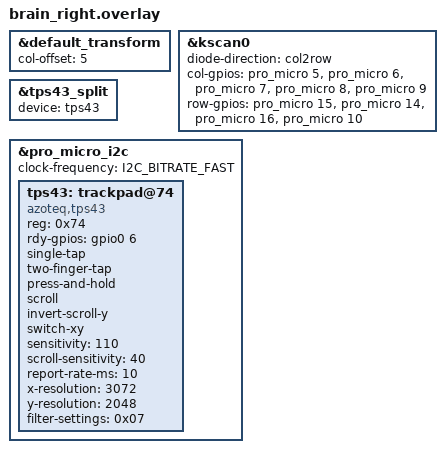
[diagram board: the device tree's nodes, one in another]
/*
 * Copyright (c) 2022 Duccio Breschi
 * Copyright (c) 2023 iamDrakkir
 * SPDX-License-Identifier: MIT
 */

#include "brain.dtsi"
#include <dt-bindings/i2c/i2c.h>

&default_transform {
    col-offset = <5>;
};

&kscan0 {
    diode-direction = "col2row";
    col-gpios
        = <&pro_micro 5 (GPIO_ACTIVE_HIGH)> // COL0
        , <&pro_micro 6 (GPIO_ACTIVE_HIGH)> // COL1
        , <&pro_micro 7 (GPIO_ACTIVE_HIGH)> // COL2
        , <&pro_micro 8 (GPIO_ACTIVE_HIGH)> // COL3
        , <&pro_micro 9 (GPIO_ACTIVE_HIGH)> // COL4
    ;
    row-gpios
        = <&pro_micro 15 (GPIO_ACTIVE_HIGH | GPIO_PULL_DOWN)> // ROW0
        , <&pro_micro 14 (GPIO_ACTIVE_HIGH | GPIO_PULL_DOWN)> // ROW1
        , <&pro_micro 16 (GPIO_ACTIVE_HIGH | GPIO_PULL_DOWN)> // ROW2
        , <&pro_micro 10 (GPIO_ACTIVE_HIGH | GPIO_PULL_DOWN)> // ROW3
    ;
};

/* ─── TPS43 Touchpad via nice!view header pins ─────────────────────────
 *
 * nice!view header (Brain PCB)       TPS43 adapter
 * ────────────────────────────       ─────────────
 * MOSI  (P0.17)  ──────────────►    SDA
 * SCK   (P0.20)  ──────────────►    SCL
 * VCC   (3.3V)   ──────────────►    VCC
 * GND            ──────────────►    GND
 * CS    (P0.06)  ──────────────►    RDY
 */

&tps43_split {
    device = <&tps43>;
};

&pro_micro_i2c {
    status = "okay";
    clock-frequency = <I2C_BITRATE_FAST>;

    tps43: trackpad@74 {
        compatible = "azoteq,tps43";
        reg = <0x74>;
        status = "okay";

        /* RDY pin — nice!view CS (P0.06) */
        rdy-gpios = <&gpio0 6 GPIO_ACTIVE_HIGH>;

        /* Gestures */
        single-tap;
        two-finger-tap;
        press-and-hold;          /* hold-to-drag ("grab") */

        /* Scrolling */
        scroll;
        invert-scroll-y;         /* revert scroll direction */

        switch-xy;

        /* Tuning */
        sensitivity = <110>;
        scroll-sensitivity = <40>;

        /* Report rate: 100Hz on active + idle-touch so slow finger
         * movement stays smooth (idle-touch default rate caused stutter). */
        report-rate-ms = <10>;

        /* Hardware resolution provides cursor gain without amplifying
         * sensor noise the way software sensitivity does. */
        x-resolution = <3072>;
        y-resolution = <2048>;

        filter-settings = <0x07>;   /* IIR + MAV + static IIR: re-add MAV to smooth jitter */

        /* enable-power-management intentionally removed: the driver's
         * PM force-suspends the chip and disables the RDY interrupt, so
         * it cannot wake on touch. Without it, the chip's own low-power
         * scan still saves power AND wakes on touch. */
    };
};
